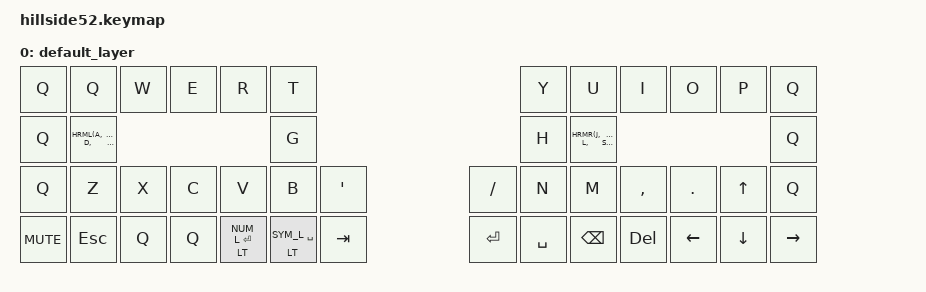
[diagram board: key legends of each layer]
/*
 * Copyright (c) 2021-2022 The ZMK Contributors
 *
 * SPDX-License-Identifier: MIT
 */

#include <behaviors.dtsi>
#include <dt-bindings/zmk/bt.h>
#include <dt-bindings/zmk/ext_power.h>
#include <dt-bindings/zmk/keys.h>
#include <dt-bindings/zmk/outputs.h>

// Layers
#define QWERTY_L 0
#define DVORAK_L 1
#define COLEMK_L 2
#define NAV_L    3
#define SYM_L    2
#define ADJ_L    5


#define Undo   LC(Z)
#define Cut    LC(X)
#define Copy   LC(C)
#define Paste  LC(V)
#define Redo   LC(Y)

// Home row mods macro
#define HRML(k1,k2,k3,k4) &ht LCTRL k1 &ht LALT k2  &ht LGUI k3 &ht LSHFT k4
#define HRMR(k1,k2,k3,k4) &ht RSHFT k1 &ht RGUI k2  &ht RALT k3 &ht RCTRL k4

#define  NUM_SPC LT(_NUM, KC_SPC)
#define SymSpace &LT SYM_L SPACE
#define NumEnter &LT NUM_L ENTER


/ {
        behaviors {
                ht: hold_tap {
                        label = "hold_tap";
                        compatible = "zmk,behavior-hold-tap";
                        #binding-cells = <2>;
                        flavor = "tap-preferred"; //krk: need to try "balanced" as well
                        tapping-term-ms = <220>;
                        quick-tap-ms = <150>;
                        global-quick-tap;
                        bindings = <&kp>, <&kp>;
                };
        };
        keymap {
                compatible = "zmk,keymap";

                default_layer {
                        bindings = <
                //╭──────────┬──────────┬──────────┬──────────┬──────────┬──────────╮                                                ╭──────────┬──────────┬──────────┬──────────┬──────────┬──────────╮
                //│          │  Q       │  W       │  E       │  R       │  T       │                                                │  Y       │  U       │  I       │  O       │  P       │  Q       │
                   &kp Q      &kp Q      &kp W      &kp E      &kp R      &kp T                                                       &kp Y      &kp U      &kp I      &kp O      &kp P      &kp Q
                //├──────────┼──────────┼──────────┼──────────┼──────────┼──────────┤                                                ├──────────┼──────────┼──────────┼──────────┼──────────┼──────────┤
                //│          │  A       │  S       │  D       │  F       │  G       │                                                │  H       │  J       │  K       │  L       │  ;       │ Q        │
                   &kp Q      HRML(A,        S,         D,         F)     &kp G                                                       &kp H      HRMR(J,        K,         L,       SEMI)    &kp Q
                //├──────────┼──────────┼──────────┼──────────┼──────────┼──────────┼──────────┤                         ├───────────┼──────────┼──────────┼──────────┼──────────┼──────────┼──────────┤
                //│          │  Z       │  X       │  C       │  V       │  B       │  '       │                         │  /        │  N       │  M       │ , <      │ . >      │  UP      │ Q        │
                   &kp Q      &kp Z      &kp X      &kp C      &kp V      &kp B      &kp SQT                              &kp SLASH   &kp N      &kp M      &kp COMMA  &kp DOT    &kp UP     &kp Q
                //├──────────┼──────────┼──────────┼──────────┼──────────┼──────────┼──────────┼──────────┤   ├──────────┼───────────┼──────────┼──────────┼──────────┼──────────┼──────────┼──────────┤
                //  MUTE     |ESC       | ?????    | xxxxxxxx |  FUNL    | num/ENTR | sym/SPC  | TAB      |   |ENTER     | SPACE     | BKSPC    | DEL      | xxxxxxxx | LEFT     |DOWN      |RIGHT     |
                   &kp C_MUTE &kp ESC    &kp Q                 &kp Q      NumEnter    SymSpace  &kp TAB        &kp ENTER  &kp SPACE   &kp BSPC   &kp DEL               &kp LEFT   &kp DOWN   &kp RIGHT
                //
                        >;
                        sensor-bindings = <&inc_dec_kp C_VOL_UP C_VOL_DN &inc_dec_kp PG_UP PG_DN>;

                };
 


        };
};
